# STM32H7S register map
File version: 1.3
CPU: CM7 r0p1, little endian, MPU, FPU, 4 interrupt priority bits
Registers are 32-bit, read-write, reset 0x0 unless marked. A register's access mark holds for its fields unless they carry their own. Offsets are from the block's base; [hi:lo] are bit positions.

## SPI1 — Serial peripheral interface
Base 0x42003000
Same registers: SPI2 0x40003800, SPI3 0x40003C00, SPI4 0x42003400, SPI5 0x42005000, SPI6 0x58001400
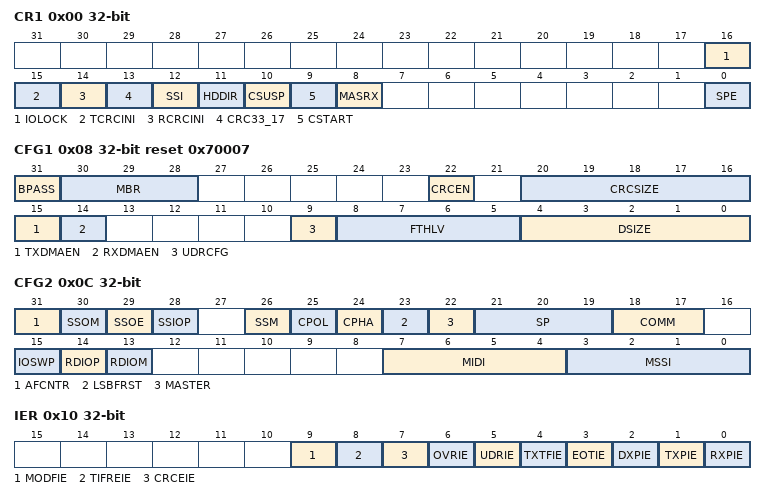
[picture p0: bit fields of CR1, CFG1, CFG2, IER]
0x00 CR1 access per field — SPI/I2S control register 1
  [16] IOLOCK rw — locking the AF configuration of associated I/Os This bit can be changed by software only when SPI is disabled (SPE = 0). It is cleared by hardware if a MODF event occurs When this bit is set, SPI_CFG2 register content cannot be modified. This bit is write-protected when SPI is enabled (SPE = 1).
    0=Unlocked (IO configuration unlocked); 1=Locked (IO configuration locked)
  [15] TCRCINI rw — CRC calculation initialization pattern control for transmitter
    0=All zeros TX CRC initialization pattern; 1=All ones TX CRC initialization pattern
  [14] RCRCINI rw — CRC calculation initialization pattern control for receiver
    0=All zeros RX CRC initialization pattern; 1=All ones RX CRC initialization pattern
  [13] CRC33_17 rw — 32-bit CRC polynomial configuration
    0=Disabled (Full size (33/17 bit) CRC polynomial is not used); 1=Enabled (Full size (33/17 bit) CRC polynomial is used)
  [12] SSI rw — internal SS signal input level This bit has an effect only when the SSM bit is set. The value of this bit is forced onto the peripheral SS input internally and the I/O value of the SS pin is ignored.
    0=SlaveSelected (0 is forced onto the SS signal and the I/O value of the SS pin is ignored); 1=SlaveNotSelected (1 is forced onto the SS signal and the I/O value of the SS pin is ignored)
  [11] HDDIR rw — Rx/Tx direction at Half-duplex mode In Half-Duplex configuration the HDDIR bit establishes the Rx/Tx direction of the data transfer. This bit is ignored in Full-Duplex or any Simplex configuration.
    0=Receiver in half duplex mode; 1=Transmitter in half duplex mode
  [10] CSUSP wo — master suspend request This bit reads as zero. In Master mode, when this bit is set by software, the CSTART bit is reset at the end of the current frame and communication is suspended. The user has to check SUSP flag to check end of the frame transaction. The Master mode communication must be suspended (using this bit or keeping TXDR empty) before going to Low-power mode. Can be used in SPI or I2S mode. After software suspension, SUSP flag must be cleared and SPI disabled and re-enabled before the next transaction starts.
    0=NotRequested (Do not request master suspend); 1=Requested (Request master suspend)
  [9] CSTART rw — master transfer start This bit can be set by software if SPI is enabled only to start an SPI or I2S/PCM communication. In SPI mode, it is cleared by hardware when end of transfer (EOT) flag is set or when a transaction suspend request is accepted. In I2S/PCM mode, it is also cleared by hardware as described in the Section 80.9.8: Stop sequence. In SPI mode, the bit is taken into account at master mode only. If transmission is enabled, communication starts or continues only if any data is available in the transmission FIFO.
    0=NotStarted (Do not start master transfer); 1=Started (Start master transfer)
  [8] MASRX rw — master automatic suspension in Receive mode This bit is set and cleared by software to control continuous SPI transfer in master receiver mode and automatic management in order to avoid overrun condition. When SPI communication is suspended by hardware automatically, it may happen that few bits of next frame are already clocked out due to internal synchronization delay. This is why, the automatic suspension is not quite reliable when size of data drops below 8 bits. In this case, a safe suspension can be achieved by combination with delay inserted between data frames applied when MIDI parameter keeps a non zero value; sum of data size and the interleaved SPI cycles should always produce interval at length of 8 SPI clock periods at minimum. After software clearing of the SUSP bit, the communication resumes and continues by subsequent bits transaction without any next constraint. Prior the SUSP bit is cleared, the user must release the RxFIFO space as much as possible by reading out all the data packets available at RxFIFO based on the RXP flag indication to prevent any subsequent suspension.
    0=Disabled (Automatic suspend in master receive-only mode disabled); 1=Enabled (Automatic suspend in master receive-only mode enabled)
  [0] SPE rw — serial peripheral enable This bit is set by and cleared by software. When SPE = 1, SPI data transfer is enabled, SPI_CFG1 and SPI_CFG2 configuration registers, CRCPOLY, UDRDR, IOLOCK bit in the SPI_CR1 register are write protected. They can be changed only when SPE = 0. When SPE = 0 any SPI operation is stopped and disabled, all the pending requests of the events with enabled interrupt are blocked except the MODF interrupt request (but their pending still propagates the request of the spi_plck clock), the SS output is deactivated at master, the RDY signal keeps not ready status at slave, the internal state machine is reseted, all the FIFOs content is flushed, CRC calculation initialized, receive data register is read zero. SPE is cleared and cannot be set when MODF error flag is active.
    0=Disabled (Peripheral disabled); 1=Enabled (Peripheral enabled)
0x04 CR2 — SPI/I2S control register 2
  [15:0] TSIZE — number of data at current transfer When these bits are changed by software, the SPI must be disabled. Endless transaction is initialized when CSTART is set while zero value is stored at TSIZE. TSIZE cannot be set to 0xFFFF respective 0x3FFF value when CRC is enabled. Note: TSIZE[15:10] bits are reserved at limited feature set instances and must be kept at reset value.
0x08 CFG1 reset 0x70007 — SPI/I2S configuration register 1
  [31] BPASS — bypass of the prescaler at master baud rate clock generator
    0=Disabled (Bypass is disabled); 1=Enabled (Bypass is enabled)
  [30:28] MBR — master baud rate prescaler setting Note: MBR setting is considered at slave working at TI mode, too (see Section 80.5.1: TI mode).
    0=Div2 (f_spi_ker_ck / 2); 1=Div4 (f_spi_ker_ck / 4); 2=Div8 (f_spi_ker_ck / 8); 3=Div16 (f_spi_ker_ck / 16); 4=Div32 (f_spi_ker_ck / 32); 5=Div64 (f_spi_ker_ck / 64); 6=Div128 (f_spi_ker_ck / 128); 7=Div256 (f_spi_ker_ck / 256)
  [22] CRCEN — hardware CRC computation enable
    0=Disabled (CRC calculation disabled); 1=Enabled (CRC calculation enabled)
  [20:16] CRCSIZE — length of CRC frame to be transacted and compared Most significant bits are taken into account from polynomial calculation when CRC result is transacted or compared. The length of the polynomial is not affected by this setting. ..... The value must be set equal or multiply of data size (DSIZE[4:0]). Its maximum size corresponds to DSIZE maximum at the instance. Note: The most significant bit at CRCSIZE bit field is reserved at the peripheral instances where data size is limited to 16-bit.
  [15] TXDMAEN — Tx DMA stream enable
    0=Disabled (Tx buffer DMA disabled); 1=Enabled (Tx buffer DMA enabled)
  [14] RXDMAEN — Rx DMA stream enable
    0=Disabled (Rx buffer DMA disabled); 1=Enabled (Rx buffer DMA enabled)
  [9] UDRCFG — behavior of slave transmitter at underrun condition For more details see Figure 962: Optional configurations of slave detecting underrun condition.
    0=Constant (Slave sends a constant underrun pattern); 1=RepeatReceived (Slave repeats last received data frame from master)
  [8:5] FTHLV — FIFO threshold level Defines number of data frames at single data packet. Size of the packet should not exceed 1/2 of FIFO space. SPI interface is more efficient if configured packet sizes are aligned with data register access parallelism: If SPI data register is accessed as a 16-bit register and DSIZE UNDER OR EQUAL 8 bit, better to select FTHLV = 2, 4, 6. If SPI data register is accessed as a 32-bit register and DSIZE> 8 bit, better to select FTHLV = 2, 4, 6, while if DSIZE UNDER OR EQUAL 8bit, better to select FTHLV = 4, 8, 12. Note: FTHLV[3:2] bits are reserved at instances with limited set of features
    0=OneFrame (1 frame); 1=TwoFrames (2 frames); 2=ThreeFrames (3 frames); 3=FourFrames (4 frames); 4=FiveFrames (5 frames); 5=SixFrames (6 frames); 6=SevenFrames (7 frames); 7=EightFrames (8 frames); 8=NineFrames (9 frames); 9=TenFrames (10 frames); 10=ElevenFrames (11 frames); 11=TwelveFrames (12 frames); 12=ThirteenFrames (13 frames); 13=FourteenFrames (14 frames); 14=FifteenFrames (15 frames); 15=SixteenFrames (16 frames)
  [4:0] DSIZE — number of bits in at single SPI data frame ..... Maximum data size can be limited up to 16-bits at some instances. At instances with limited set of features, DSIZE[2:0] bits are reserved and must be kept at reset state. DSIZE[4:3] bits then control next settings of data size: 00xxx: 8-bits 01xxx: 16-bits 10xxx: 24-bits Note: 11xxx: 32-bits.
0x0C CFG2 — SPI/I2S configuration register 2
  [31] AFCNTR — alternate function GPIOs control This bit is taken into account when SPE = 0 only When SPI must be disabled temporary for a specific configuration reason (for example CRC reset, CPHA or HDDIR change) setting this bit prevents any glitches on the associated outputs configured at alternate function mode by keeping them forced at state corresponding the current SPI configuration. Note: This bit can be also used in PCM and I2S modes. Note: The bit AFCNTR must not be set, when the block is in slave mode.
    0=NotControlled (Peripheral takes no control of GPIOs while disabled); 1=Controlled (Peripheral controls GPIOs while disabled)
  [30] SSOM — SS output management in Master mode This bit is taken into account in Master mode when SSOE is enabled. It allows the SS output to be configured between two consecutive data transfers.
    0=Asserted (SS is asserted until data transfer complete); 1=NotAsserted (Data frames interleaved with SS not asserted during MIDI)
  [29] SSOE — SS output enable This bit is taken into account in Master mode only
    0=Disabled (SS output is disabled in master mode); 1=Enabled (SS output is enabled in master mode)
  [28] SSIOP — SS input/output polarity
    0=ActiveLow (Low level is active for SS signal); 1=ActiveHigh (High level is active for SS signal)
  [26] SSM — software management of SS signal input When master uses hardware SS output (SSM = 0 and SSOE = 1) the SS signal input is forced to not active state internally to prevent master mode fault error.
    0=Disabled (Software slave management disabled); 1=Enabled (Software slave management enabled)
  [25] CPOL — clock polarity
    0=IdleLow (CK to 0 when idle); 1=IdleHigh (CK to 1 when idle)
  [24] CPHA — clock phase
    0=FirstEdge (The first clock transition is the first data capture edge); 1=SecondEdge (The second clock transition is the first data capture edge)
  [23] LSBFRST — data frame format Note: This bit can be also used in PCM and I2S modes.
    0=MSBFirst (Data is transmitted/received with the MSB first); 1=LSBFirst (Data is transmitted/received with the LSB first)
  [22] MASTER — SPI Master
    0=Slave configuration; 1=Master configuration
  [21:19] SP — serial protocol others: reserved, must not be used
    0=Motorola SPI protocol; 1=TI (TI SPI protocol)
  [18:17] COMM — SPI Communication Mode
    0=FullDuplex; 1=Transmitter (Simplex transmitter only); 2=Receiver (Simplex receiver only); 3=HalfDuplex
  [15] IOSWP — swap functionality of MISO and MOSI pins When this bit is set, the function of MISO and MOSI pins alternate functions are inverted. Original MISO pin becomes MOSI and original MOSI pin becomes MISO. Note: This bit can be also used in PCM and I2S modes to swap SDO and SDI pins.
    0=Disabled (MISO and MOSI not swapped); 1=Enabled (MISO and MOSI swapped)
  [14] RDIOP — RDY signal input/output polarity
    0=high level of the signal means the slave is ready for communication; 1=Low (low level of the signal means the slave is ready for communication)
  [13] RDIOM — RDY signal input/output management Note: When DSIZE at the SPI_CFG1 register is configured shorter than 8-bit, the RDIOM bit must be kept at zero.
    0=Active (RDY signal is defined internally fixed as permanently active (RDIOP setting has no effect)); 1=Pin (RDY signal is overtaken from alternate function input (at master case) or output (at slave case) of the dedicated pin (RDIOP setting takes effect))
  [7:4] MIDI — master Inter-Data Idleness Specifies minimum time delay (expressed in SPI clock cycles periods) inserted between two consecutive data frames in Master mode. ... Note: This feature is not supported in TI mode.
  [3:0] MSSI — Master SS Idleness Specifies an extra delay, expressed in number of SPI clock cycle periods, inserted additionally between active edge of SS opening a session and the beginning of the first data frame of the session in Master mode when SSOE is enabled. ... This feature is not supported in TI mode. Note: To include the delay, the SPI must be disabled and re-enabled between sessions.
0x10 IER — SPI/I2S interrupt enable register
  [all] fields
    0=Disabled (Interrupt disabled); 1=Enabled (Interrupt enabled)
  [9] MODFIE — mode Fault interrupt enable
  [8] TIFREIE — TIFRE interrupt enable
  [7] CRCEIE — CRC error interrupt enable
  [6] OVRIE — OVR interrupt enable
  [5] UDRIE — UDR interrupt enable
  [4] TXTFIE — TXTFIE interrupt enable
  [3] EOTIE — EOT, SUSP and TXC interrupt enable
  [2] DXPIE — DXP interrupt enabled DXPIE is set by software and cleared by TXTF flag set event.
  [1] TXPIE — TXP interrupt enable TXPIE is set by software and cleared by TXTF flag set event.
  [0] RXPIE — RXP interrupt enable
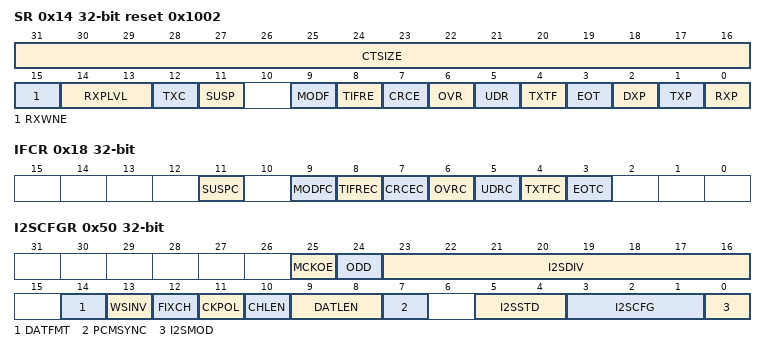
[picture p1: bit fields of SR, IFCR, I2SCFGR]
0x14 SR ro reset 0x1002 — SPI/I2S status register
  [31:16] CTSIZE — number of data frames remaining in current TSIZE session The value is not quite reliable when traffic is ongoing on bus . Note: CTSIZE[15:0] bits are not available in instances with limited set of features.
  [15] RXWNE — RxFIFO word not empty Note: This bit value does not depend on DSIZE setting and keeps together with RXPLVL[1:0] information about RxFIFO occupancy by residual data.
    0=Less than 32-bit data frame received; 1=At least 32-bit data frame received
  [14:13] RXPLVL — RxFIFO packing level When RXWNE = 0 and data size is set up to 16-bit, the value gives number of remaining data frames persisting at RxFIFO. Note: (*): Possible value when data size is set up to 8-bit only. When data size is greater than 16-bit, these bits are always read as 00. In that consequence, the single data frame received at the FIFO cannot be detected neither by RWNE nor by RXPLVL bits if data size is set from 17 to 24 bits. The user must then apply other methods to detect the number of data received, such as monitor the EOT event when TSIZE > 0 or RXP events when FTHLV = 0.
    0=Zero frames beyond packing ratio available; 1=One frame beyond packing ratio available; 2=TwoFrames (Two frame beyond packing ratio available); 3=ThreeFrames (Three frame beyond packing ratio available)
  [12] TXC — TxFIFO transmission complete The flag behavior depends on TSIZE setting. When TSIZE = 0, the TXC is changed by hardware exclusively and it raises each time the TxFIFO becomes empty and there is no activity on the bus. If TSIZE different from 0 there is no specific reason to monitor TXC as it just copies the EOT flag value including its software clearing. The TXC generates an interrupt when EOTIE is set. This flag is set when SPI is reset or disabled.
    0=Ongoing (Transmission ongoing); 1=Completed (Transmission completed)
  [11] SUSP — suspension status In Master mode, SUSP is set by hardware either as soon as the current frame is completed after CSUSP request is done or at master automatic suspend receive mode (MASRX bit is set at SPI_CR1 register) on RxFIFO full condition. SUSP generates an interrupt when EOTIE is set. This bit must be cleared prior SPI is disabled and this is done by writing 1 to SUSPC bit of SPI_IFCR exclusively.
    0=NotSuspended (Master not suspended); 1=Suspended (Master suspended)
  [9] MODF — mode fault When MODF is set, SPE and IOLOCK bits of SPI_CR1 register are reset and setting SPE again is blocked until MODF is cleared. This bit is cleared by writing 1 to MODFC bit of SPI_IFCR exclusively.
    0=NoFault (No mode fault detected); 1=Fault (Mode fault detected)
  [8] TIFRE — TI frame format error This bit is cleared by writing 1 to TIFREC bit of SPI_IFCR exclusively.
    0=NoError (TI frame format error detected); 1=Error (TI frame format error detected)
  [7] CRCE — CRC error This bit is cleared when SPI is re-enabled or by writing 1 to CRCEC bit of SPI_IFCR optionally.
    0=NoError (No CRC error detected); 1=Error (CRC error detected)
  [6] OVR — overrun This bit is cleared when SPI is re-enabled or by writing 1 to OVRC bit of SPI_IFCR optionally.
    0=No overrun occurred; 1=Overrun occurred
  [5] UDR — underrun This bit is cleared when SPI is re-enabled or by writing 1 to UDRC bit of SPI_IFCR optionally. Note: In SPI mode, the UDR flag applies to Slave mode only. In I2S/PCM mode, (when available) this flag applies to Master and Slave mode
    0=No underrun occurred; 1=Underrun occurred
  [4] TXTF — transmission transfer filled TXTF is set by hardware as soon as all of the data packets in a transfer have been submitted for transmission by application software or DMA, that is when TSIZE number of data have been pushed into the TxFIFO. This bit is cleared by software write 1 to TXTFC bit of SPI_IFCR exclusively. TXTF flag triggers an interrupt if TXTFIE bit is set. TXTF setting clears the TXPIE and DXPIE masks so to off-load application software from calculating when to disable TXP and DXP interrupts.
    0=NotCompleted (Transmission buffer incomplete); 1=Completed (Transmission buffer filled with at least one transfer)
  [3] EOT — end of transfer EOT is set by hardware as soon as a full transfer is complete, that is when SPI is re-enabled or when TSIZE number of data have been transmitted and/or received on the SPI. EOT is cleared when SPI is re-enabled or by writing 1 to EOTC bit of SPI_IFCR optionally. EOT flag triggers an interrupt if EOTIE bit is set. If DXP flag is used until TXTF flag is set and DXPIE is cleared, EOT can be used to download the last packets contained into RxFIFO in one-shot. In master, EOT event terminates the data transaction and handles SS output optionally. When CRC is applied, the EOT event is extended over the CRC frame transaction. To restart the internal state machine properly, SPI is strongly suggested to be disabled and re-enabled before next transaction starts despite its setting is not changed.
    0=NotCompleted (Transfer ongoing or not started); 1=Completed (Transfer complete)
  [2] DXP — duplex packet DXP flag is set whenever both TXP and RXP flags are set regardless SPI mode.
    0=Unavailable (Duplex packet unavailable: no space for transmission and/or no data received); 1=Available (Duplex packet available: space for transmission and data received)
  [1] TXP — Tx-packet space available TXP flag can be changed only by hardware. Its value depends on the physical size of the FIFO and its threshold (FTHLV[3:0]), data frame size (DSIZE[4:0] in SPI mode and respective DATLEN[1:0] in I2S/PCM mode), and actual communication flow. If the data packet is stored by performing consecutive write operations to SPI_TXDR, TXP flag must be checked again once a complete data packet is stored at TxFIFO. TXP is set despite SPI TxFIFO becomes inaccessible when SPI is reset or disabled.
    0=Full (Tx buffer full); 1=NotFull (Tx buffer not full)
  [0] RXP — Rx-packet available The flag is changed by hardware. It monitors the total number of data currently available at RxFIFO if SPI is enabled. RXP value depends on the FIFO threshold (FTHLV[3:0]), data frame size (DSIZE[4:0] in SPI mode and DATLEN[1:0] in I2S/PCM mode), and actual communication flow. If the data packet is read by performing consecutive read operations from SPI_RXDR, RXP flag must be checked again once a complete data packet is read out from RxFIFO.
    0=Empty (Rx buffer empty); 1=NotEmpty (Rx buffer not empty)
0x18 IFCR wo — SPI/I2S interrupt/status flags clear register
  [all] fields
    1=Clear interrupt flag
  [11] SUSPC write-1-clears — Suspend flag clear Writing a 1 into this bit clears SUSP flag in the SPI_SR register
  [9] MODFC write-1-clears — mode fault flag clear Writing a 1 into this bit clears MODF flag in the SPI_SR register
  [8] TIFREC write-1-clears — TI frame format error flag clear Writing a 1 into this bit clears TIFRE flag in the SPI_SR register
  [7] CRCEC write-1-clears — CRC error flag clear Writing a 1 into this bit clears CRCE flag in the SPI_SR register
  [6] OVRC write-1-clears — overrun flag clear Writing a 1 into this bit clears OVR flag in the SPI_SR register
  [5] UDRC write-1-clears — underrun flag clear Writing a 1 into this bit clears UDR flag in the SPI_SR register
  [4] TXTFC write-1-clears — transmission transfer filled flag clear Writing a 1 into this bit clears TXTF flag in the SPI_SR register
  [3] EOTC write-1-clears — end of transfer flag clear Writing a 1 into this bit clears EOT flag in the SPI_SR register
0x20 TXDR wo — SPI/I2S transmit data register
  [31:0] TXDR — transmit data register The register serves as an interface with TxFIFO. A write to it accesses TxFIFO. Note: In SPI mode, data is always right-aligned. Alignment of data at I2S mode depends on DATLEN and DATFMT setting. Unused bits are ignored when writing to the register, and read as zero when the register is read. Note: DR can be accessed byte-wise (8-bit access): in this case only one data-byte is written by single access. Note: halfword-wise (16 bit access) in this case 2 data-bytes or 1 halfword-data can be written by single access. Note: word-wise (32 bit access). In this case 4 data-bytes or 2 halfword-data or word-data can be written by single access. Note: Write access of this register less than the configured data size is forbidden.
0x20 TXDR16 16-bit wo (alternate view of TXDR) — Direct 16-bit access to transmit data register
  [15:0] TXDR — Transmit data register
0x20 TXDR8 8-bit wo (alternate view of TXDR) — Direct 8-bit access to transmit data register
  [7:0] TXDR — Transmit data register
0x30 RXDR ro — SPI/I2S receive data register
  [31:0] RXDR — receive data register The register serves as an interface with RxFIFO. When it is read, RxFIFO is accessed. Note: In SPI mode, data is always right-aligned. Alignment of data at I2S mode depends on DATLEN and DATFMT setting. Unused bits are read as zero when the register is read. Writing to the register is ignored. Note: DR can be accessed byte-wise (8-bit access): in this case only one data-byte is read by single access Note: halfword-wise (16 bit access) in this case 2 data-bytes or 1 halfword-data can be read by single access Note: word-wise (32 bit access). In this case 4 data-bytes or 2 halfword-data or word-data can be read by single access. Note: Read access of this register less than the configured data size is forbidden.
0x30 RXDR16 16-bit ro (alternate view of RXDR) — Direct 16-bit access to receive data register
  [15:0] RXDR — Receive data register
0x30 RXDR8 8-bit ro (alternate view of RXDR) — Direct 8-bit access to receive data register
  [7:0] RXDR — Receive data register
0x40 CRCPOLY reset 0x107 — SPI/I2S polynomial register
  [31:0] CRCPOLY — CRC polynomial register This register contains the polynomial for the CRC calculation. The default 9-bit polynomial setting 0x107 corresponds to default 8-bit setting of DSIZE. It is compatible with setting 0x07 used in other ST products with fixed length of the polynomial string, where the most significant bit of the string is always kept hidden. Length of the polynomial is given by the most significant bit of the value stored in this register. It must be set greater than DSIZE. CRC33_17 bit must be set additionally with CRCPOLY register when DSIZE is configured to maximum 32-bit or 16-bit size and CRC is enabled (to keep polynomial length grater than data size). Note: CRCPOLY[31:16] bits are reserved at instances with data size limited to 16-bit. There is no constrain when 32-bit access is applied at these addresses. Reserved bits 31-16 are always read zero while any write to them is ignored.
0x44 TXCRC ro — SPI/I2S transmitter CRC register
  [31:0] TXCRC — CRC register for transmitter When CRC calculation is enabled, the TXCRC[31:0] bits contain the computed CRC value of the subsequently transmitted bytes. CRC calculation is initialized when the CRCEN bit of SPI_CR1 is written to 1 or when a data block is transacted completely. The CRC is calculated serially using the polynomial programmed in the SPI_CRCPOLY register. The number of bits considered at calculation depends on SPI_CRCPOLY register and CRCSIZE bits settings at SPI_CFG1 register. Note: A read to this register when the communication is ongoing may return an incorrect value. Note: not used for the I<sup>2</sup>S mode. Note: TXCRC[31-16] bits are reserved at instances with data size limited to 16-bit. There is no constrain when 32-bit access is applied at these addresses. Reserved bits 31-16 are always read zero while any write to them is ignored. Note: The configuration of CRCSIZE bit field is not taken into account when the content of this register is read by software. No masking is applied for unused bits in this case.
0x48 RXCRC ro — SPI/I2S receiver CRC register
  [31:0] RXCRC — CRC register for receiver When CRC calculation is enabled, the RXCRC[31:0] bits contain the computed CRC value of the subsequently received bytes. CRC calculation is initialized when the CRCEN bit of SPI_CR1 is written to 1 or when a data block is transacted completely. The CRC is calculated serially using the polynomial programmed in the SPI_CRCPOLY register. The number of bits considered at calculation depends on SPI_CRCPOLY register and CRCSIZE bits settings at SPI_CFG1 register. Note: A read to this register when the communication is ongoing may return an incorrect value. Note: Not used for the I<sup>2</sup>S mode. Note: RXCRC[31-16] bits are reserved at the peripheral instances with data size limited to 16-bit. There is no constrain when 32-bit access is applied at these addresses. Reserved bits 31-16 are always read zero while any write to them is ignored. Note: The configuration of CRCSIZE bit field is not taken into account when the content of this register is read by software. No masking is applied for unused bits in this case.
0x4C UDRDR — SPI/I2S underrun data register
  [31:0] UDRDR — data at slave underrun condition The register is taken into account in Slave mode and at underrun condition only. The number of bits considered depends on DSIZE bit settings of the SPI_CFG1 register. Underrun condition handling depends on setting UDRCFG bit at SPI_CFG1 register. Note: UDRDR[31-16] bits are reserved at the peripheral instances with data size limited to 16-bit. There is no constraint when 32-bit access is applied at these addresses. Reserved bits 31-16 are always read zero while any write to them is ignored.
0x50 I2SCFGR — SPI/I2S configuration register
  [25] MCKOE — master clock output enable
    0=Disabled (Master clock output disabled); 1=Enabled (Master clock output enabled)
  [24] ODD — odd factor for the prescaler Refer to Section 80.9.9: Clock generator for details
    0=Even (Real divider value is I2SDIV*2); 1=Odd (Real divider value is I2SDIV*2 + 1)
  [23:16] I2SDIV — I<sup>2</sup>S linear prescaler I2SDIV can take any values except the value 1, when ODD is also equal to 1. Refer to Section 80.9.9: Clock generator for details
  [14] DATFMT — data format
    0=RightAligned (The data inside RXDR and TXDR are right aligned); 1=LeftAligned (The data inside RXDR and TXDR are left aligned)
  [13] WSINV — word select inversion This bit is used to invert the default polarity of WS signal. In MSB or LSB justified mode, the left channel is transferred when WS is HIGH, and the right channel when WS is LOW. In PCM short mode the data transfer starts at the falling edge of WS, while it starts at the rising edge of WS in PCM long mode. In MSB or LSB justified mode, the left channel is transfered when WS is LOW, and right channel when WS is HIGH. In PCM short mode the data transfer starts at the rising edge of WS, while it starts at the falling edge of WS in PCM long mode.
    0=Disabled (Word select inversion disabled); 1=Enabled (Word select inversion enabled)
  [12] FIXCH — fixed channel length in slave
    0=NotFixed (The channel length in slave mode is different from 16 or 32 bits (CHLEN not taken into account)); 1=Fixed (The channel length in slave mode is supposed to be 16 or 32 bits (according to CHLEN))
  [11] CKPOL — serial audio clock polarity
    0=SampleOnRising (Signals are sampled on rising and changed on falling clock edges); 1=SampleOnFalling (Signals are sampled on falling and changed on rising clock edges)
  [10] CHLEN — channel length (number of bits per audio channel)
    0=Bits16 (16 bit per channel); 1=Bits32 (32 bit per channel)
  [9:8] DATLEN — data length to be transferred. Data width of 24 and 32 bits are not always supported, (DATLEN = 01 or 10), refer to Section 80.3: SPI implementation to check the supported data size.
    0=Bits16 (16 bit data length); 1=Bits24 (24 bit data length); 2=Bits32 (32 bit data length)
  [7] PCMSYNC — PCM frame synchronization
    0=Short PCM frame synchronization; 1=Long PCM frame synchronization
  [5:4] I2SSTD — I<sup>2</sup>S standard selection For more details on I<sup>2</sup>S standards, refer to Section 80.9.5: Supported audio protocols
    0=Philips (I2S Philips standard); 1=LeftAligned (MSB/left justified standard); 2=RightAligned (LSB/right justified standard); 3=PCM (PCM standard)
  [3:1] I2SCFG — I2S configuration mode others, not used
    0=SlaveTransmit; 1=SlaveReceive (Slave, recteive); 2=MasterTransmit; 3=MasterReceive; 4=SlaveFullDuplex; 5=MasterFullDuplex
  [0] I2SMOD — I2S mode selection
    0=SPI (SPI mode selected); 1=I2S (I2S/PCM mode selected)
